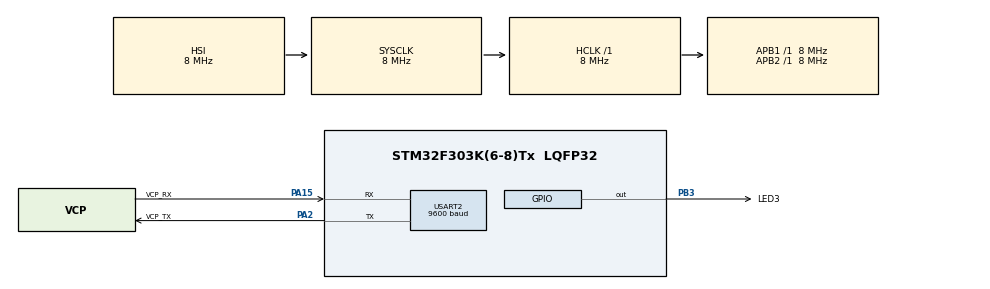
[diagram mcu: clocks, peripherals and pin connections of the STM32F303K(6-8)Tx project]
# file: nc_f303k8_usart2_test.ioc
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Mcu.Family=STM32F3
Mcu.Name=STM32F303K(6-8)Tx
Mcu.Package=LQFP32
NVIC.PriorityGroup=NVIC_PRIORITYGROUP_4
PA13.GPIO_Label=SWDIO
PA13.Mode=Serial_Wire
PA13.Signal=SYS_JTMS-SWDIO
PA14.GPIO_Label=SWCLK
PA14.Mode=Serial_Wire
PA14.Signal=SYS_JTCK-SWCLK
PA15.GPIO_Label=VCP_RX
PA15.Mode=Asynchronous
PA15.Signal=USART2_RX
PA2.GPIO_Label=VCP_TX
PA2.Mode=Asynchronous
PA2.Signal=USART2_TX
PB3.GPIO_Label=LED3
PB3.Signal=GPIO_Output
ProjectManager.HeapSize=0x200
ProjectManager.StackSize=0x400
ProjectManager.TargetToolchain=SW4STM32
RCC.AHBFreq_Value=8000000
RCC.APB1Freq_Value=8000000
RCC.APB2Freq_Value=8000000
RCC.CortexFreq_Value=8000000
RCC.HSE_VALUE=8000000
RCC.HSI_VALUE=8000000
RCC.SYSCLKFreq_VALUE=8000000
USART2.BaudRate=9600
USART2.DMADisableonRxErrorParam=UART_ADVFEATURE_DMA_DISABLEONRXERROR
USART2.WordLength=UART_WORDLENGTH_8B
board=NUCLEO-F303K8

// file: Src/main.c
/**
  ******************************************************************************
  * File Name          : main.c
  * Description        : Main program body
  ******************************************************************************
  *
  * COPYRIGHT(c) 2016 STMicroelectronics
  *
  * Redistribution and use in source and binary forms, with or without modification,
  * are permitted provided that the following conditions are met:
  *   1. Redistributions of source code must retain the above copyright notice,
  *      this list of conditions and the following disclaimer.
  *   2. Redistributions in binary form must reproduce the above copyright notice,
  *      this list of conditions and the following disclaimer in the documentation
  *      and/or other materials provided with the distribution.
  *   3. Neither the name of STMicroelectronics nor the names of its contributors
  *      may be used to endorse or promote products derived from this software
  *      without specific prior written permission.
  *
  * THIS SOFTWARE IS PROVIDED BY THE COPYRIGHT HOLDERS AND CONTRIBUTORS "AS IS"
  * AND ANY EXPRESS OR IMPLIED WARRANTIES, INCLUDING, BUT NOT LIMITED TO, THE
  * IMPLIED WARRANTIES OF MERCHANTABILITY AND FITNESS FOR A PARTICULAR PURPOSE ARE
  * DISCLAIMED. IN NO EVENT SHALL THE COPYRIGHT HOLDER OR CONTRIBUTORS BE LIABLE
  * FOR ANY DIRECT, INDIRECT, INCIDENTAL, SPECIAL, EXEMPLARY, OR CONSEQUENTIAL
  * DAMAGES (INCLUDING, BUT NOT LIMITED TO, PROCUREMENT OF SUBSTITUTE GOODS OR
  * SERVICES; LOSS OF USE, DATA, OR PROFITS; OR BUSINESS INTERRUPTION) HOWEVER
  * CAUSED AND ON ANY THEORY OF LIABILITY, WHETHER IN CONTRACT, STRICT LIABILITY,
  * OR TORT (INCLUDING NEGLIGENCE OR OTHERWISE) ARISING IN ANY WAY OUT OF THE USE
  * OF THIS SOFTWARE, EVEN IF ADVISED OF THE POSSIBILITY OF SUCH DAMAGE.
  *
  ******************************************************************************
  */
#include "main.h"
#include "stm32f3xx_hal.h"

UART_HandleTypeDef huart2;

/* USER CODE BEGIN PV */
/* Private variables ---------------------------------------------------------*/
#define INITMSG "ST-Link UART V-Com output\r\n"

/* USER CODE END PV */

void SystemClock_Config(void);
void Error_Handler(void);
static void MX_GPIO_Init(void);
static void MX_USART2_UART_Init(void);

/* USER CODE BEGIN PFP */
/* Private function prototypes -----------------------------------------------*/

/* USER CODE END PFP */

int main(void)
{

  /* MCU Configuration----------------------------------------------------------*/

  /* Reset of all peripherals, Initializes the Flash interface and the Systick. */
  HAL_Init();

  /* Configure the system clock */
  SystemClock_Config();

  /* Initialize all configured peripherals */
  MX_GPIO_Init();
  MX_USART2_UART_Init();

  /* USER CODE BEGIN 2 */
  HAL_UART_Transmit(&huart2, (uint8_t*)INITMSG, strlen(INITMSG), 5000);

  /* USER CODE END 2 */

  /* Infinite loop */
  /* USER CODE BEGIN WHILE */
  while (1)
  {
    char buff[32];
    int len = 0;
    char ch;
    do {
      HAL_UART_Receive(&huart2, (uint8_t*)(&ch), 1, HAL_MAX_DELAY);
      buff[len++] = ch;
    } while (len < 32 && (ch != '\r'));

    HAL_UART_Transmit(&huart2, buff, len, 5000);
    HAL_UART_Transmit(&huart2, "\n", 1, 5000);
  /* USER CODE END WHILE */

  }

}

/** System Clock Configuration
*/
void SystemClock_Config(void)
{

  RCC_OscInitTypeDef RCC_OscInitStruct;
  RCC_ClkInitTypeDef RCC_ClkInitStruct;

    /**Initializes the CPU, AHB and APB busses clocks
    */
  RCC_OscInitStruct.OscillatorType = RCC_OSCILLATORTYPE_HSI;
  RCC_OscInitStruct.HSIState = RCC_HSI_ON;
  RCC_OscInitStruct.HSICalibrationValue = 16;
  RCC_OscInitStruct.PLL.PLLState = RCC_PLL_NONE;
  if (HAL_RCC_OscConfig(&RCC_OscInitStruct) != HAL_OK)
  {
    Error_Handler();
  }

    /**Initializes the CPU, AHB and APB busses clocks
    */
  RCC_ClkInitStruct.ClockType = RCC_CLOCKTYPE_HCLK|RCC_CLOCKTYPE_SYSCLK
                              |RCC_CLOCKTYPE_PCLK1|RCC_CLOCKTYPE_PCLK2;
  RCC_ClkInitStruct.SYSCLKSource = RCC_SYSCLKSOURCE_HSI;
  RCC_ClkInitStruct.AHBCLKDivider = RCC_SYSCLK_DIV1;
  RCC_ClkInitStruct.APB1CLKDivider = RCC_HCLK_DIV1;
  RCC_ClkInitStruct.APB2CLKDivider = RCC_HCLK_DIV1;

  if (HAL_RCC_ClockConfig(&RCC_ClkInitStruct, FLASH_LATENCY_0) != HAL_OK)
  {
    Error_Handler();
  }

    /**Configure the Systick interrupt time
    */
  HAL_SYSTICK_Config(HAL_RCC_GetHCLKFreq()/1000);

    /**Configure the Systick
    */
  HAL_SYSTICK_CLKSourceConfig(SYSTICK_CLKSOURCE_HCLK);

  /* SysTick_IRQn interrupt configuration */
  HAL_NVIC_SetPriority(SysTick_IRQn, 0, 0);
}

/* USART2 init function */
static void MX_USART2_UART_Init(void)
{

  huart2.Instance = USART2;
  huart2.Init.BaudRate = 9600;
  huart2.Init.WordLength = UART_WORDLENGTH_8B;
  huart2.Init.StopBits = UART_STOPBITS_1;
  huart2.Init.Parity = UART_PARITY_NONE;
  huart2.Init.Mode = UART_MODE_TX_RX;
  huart2.Init.HwFlowCtl = UART_HWCONTROL_NONE;
  huart2.Init.OverSampling = UART_OVERSAMPLING_16;
  huart2.Init.OneBitSampling = UART_ONE_BIT_SAMPLE_DISABLE;
  huart2.AdvancedInit.AdvFeatureInit = UART_ADVFEATURE_DMADISABLEONERROR_INIT;
  huart2.AdvancedInit.DMADisableonRxError = UART_ADVFEATURE_DMA_DISABLEONRXERROR;
  if (HAL_UART_Init(&huart2) != HAL_OK)
  {
    Error_Handler();
  }

}

/** Configure pins as
        * Analog
        * Input
        * Output
        * EVENT_OUT
        * EXTI
*/
static void MX_GPIO_Init(void)
{

  GPIO_InitTypeDef GPIO_InitStruct;

  /* GPIO Ports Clock Enable */
  __HAL_RCC_GPIOA_CLK_ENABLE();
  __HAL_RCC_GPIOB_CLK_ENABLE();

  /*Configure GPIO pin Output Level */
  HAL_GPIO_WritePin(LED3_GPIO_Port, LED3_Pin, GPIO_PIN_RESET);

  /*Configure GPIO pin : LED3_Pin */
  GPIO_InitStruct.Pin = LED3_Pin;
  GPIO_InitStruct.Mode = GPIO_MODE_OUTPUT_PP;
  GPIO_InitStruct.Pull = GPIO_NOPULL;
  GPIO_InitStruct.Speed = GPIO_SPEED_FREQ_LOW;
  HAL_GPIO_Init(LED3_GPIO_Port, &GPIO_InitStruct);

}

void Error_Handler(void)
{
  while(1)
  {
  }
}

/************************ (C) COPYRIGHT STMicroelectronics *****END OF FILE****/
